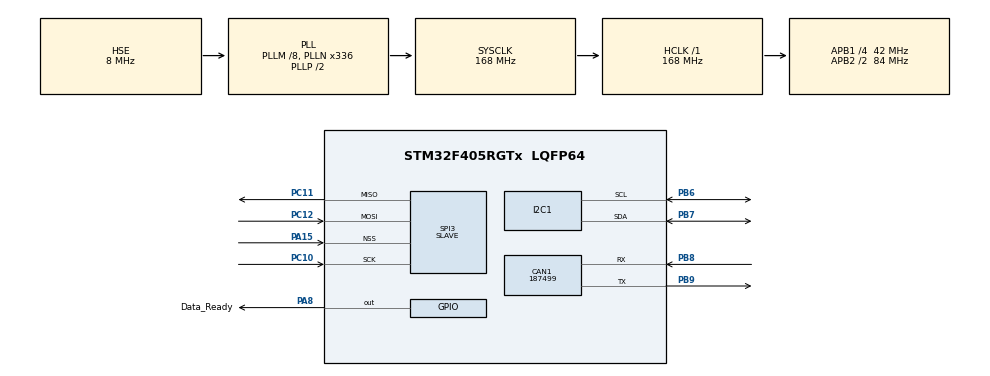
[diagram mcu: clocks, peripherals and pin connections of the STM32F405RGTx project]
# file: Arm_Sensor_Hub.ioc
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CAN1.BS1=CAN_BS1_11TQ
CAN1.BS2=CAN_BS2_2TQ
CAN1.CalculateBaudRate=187499
CAN1.CalculateTimeBit=5333
CAN1.CalculateTimeQuantum=380.95238095238096
Dma.Request0=SPI3_RX
Dma.Request1=SPI3_TX
Dma.SPI3_RX.0.Direction=DMA_PERIPH_TO_MEMORY
Dma.SPI3_RX.0.FIFOMode=DMA_FIFOMODE_DISABLE
Dma.SPI3_RX.0.Instance=DMA1_Stream0
Dma.SPI3_RX.0.MemDataAlignment=DMA_MDATAALIGN_BYTE
Dma.SPI3_RX.0.MemInc=DMA_MINC_ENABLE
Dma.SPI3_RX.0.Mode=DMA_NORMAL
Dma.SPI3_RX.0.PeriphDataAlignment=DMA_PDATAALIGN_BYTE
Dma.SPI3_RX.0.PeriphInc=DMA_PINC_DISABLE
Dma.SPI3_RX.0.Priority=DMA_PRIORITY_VERY_HIGH
Dma.SPI3_TX.1.Direction=DMA_MEMORY_TO_PERIPH
Dma.SPI3_TX.1.FIFOMode=DMA_FIFOMODE_DISABLE
Dma.SPI3_TX.1.Instance=DMA1_Stream5
Dma.SPI3_TX.1.MemDataAlignment=DMA_MDATAALIGN_BYTE
Dma.SPI3_TX.1.MemInc=DMA_MINC_ENABLE
Dma.SPI3_TX.1.Mode=DMA_NORMAL
Dma.SPI3_TX.1.PeriphDataAlignment=DMA_PDATAALIGN_BYTE
Dma.SPI3_TX.1.PeriphInc=DMA_PINC_DISABLE
Dma.SPI3_TX.1.Priority=DMA_PRIORITY_HIGH
FREERTOS.Tasks01=defaultTask,24,128,StartDefaultTask,Default,NULL,Dynamic,NULL,NULL
I2C1.I2C_Mode=I2C_Fast
Mcu.Family=STM32F4
Mcu.Name=STM32F405RGTx
Mcu.Package=LQFP64
NVIC.DMA1_Stream0_IRQn=true\:5\:0\:true\:false\:true\:true\:false\:true\:true
NVIC.DMA1_Stream5_IRQn=true\:6\:0\:true\:false\:true\:true\:false\:true\:true
NVIC.PriorityGroup=NVIC_PRIORITYGROUP_4
NVIC.SPI3_IRQn=true\:5\:0\:false\:false\:true\:true\:true\:true\:true
NVIC.TIM6_DAC_IRQn=true\:15\:0\:false\:false\:true\:false\:false\:true\:true
NVIC.TimeBase=TIM6_DAC_IRQn
NVIC.TimeBaseIP=TIM6
PA13.Mode=Serial_Wire
PA13.Signal=SYS_JTMS-SWDIO
PA14.Mode=Serial_Wire
PA14.Signal=SYS_JTCK-SWCLK
PA15.Mode=NSS_Signal_Hard_Input
PA15.Signal=SPI3_NSS
PA8.GPIO_Label=Data_Ready
PA8.Signal=GPIO_Output
PB6.Mode=I2C
PB6.Signal=I2C1_SCL
PB7.Mode=I2C
PB7.Signal=I2C1_SDA
PB8.Mode=CAN_Activate
PB8.Signal=CAN1_RX
PB9.Mode=CAN_Activate
PB9.Signal=CAN1_TX
PC10.Mode=Full_Duplex_Slave
PC10.Signal=SPI3_SCK
PC11.Mode=Full_Duplex_Slave
PC11.Signal=SPI3_MISO
PC12.Mode=Full_Duplex_Slave
PC12.Signal=SPI3_MOSI
PH0-OSC_IN.Mode=HSE-External-Oscillator
PH0-OSC_IN.Signal=RCC_OSC_IN
PH1-OSC_OUT.Mode=HSE-External-Oscillator
PH1-OSC_OUT.Signal=RCC_OSC_OUT
ProjectManager.HeapSize=0x200
ProjectManager.StackSize=0x400
ProjectManager.TargetToolchain=CMake
RCC.48MHZClocksFreq_Value=48000000
RCC.AHBFreq_Value=168000000
RCC.APB1CLKDivider=RCC_HCLK_DIV4
RCC.APB1Freq_Value=42000000
RCC.APB1TimFreq_Value=84000000
RCC.APB2CLKDivider=RCC_HCLK_DIV2
RCC.APB2Freq_Value=84000000
RCC.APB2TimFreq_Value=168000000
RCC.CortexFreq_Value=168000000
RCC.EnbaleCSS=true
RCC.HCLKFreq_Value=168000000
RCC.HSE_VALUE=8000000
RCC.HSI_VALUE=16000000
RCC.LSE_VALUE=32768
RCC.PLLM=8
RCC.PLLN=336
RCC.PLLQ=7
RCC.PLLSourceVirtual=RCC_PLLSOURCE_HSE
RCC.SYSCLKFreq_VALUE=168000000
RCC.SYSCLKSource=RCC_SYSCLKSOURCE_PLLCLK
RCC.VCOOutputFreq_Value=336000000
SPI3.Direction=SPI_DIRECTION_2LINES
SPI3.Mode=SPI_MODE_SLAVE
SPI3.VirtualNSS=VM_NSSHARD
SPI3.VirtualType=VM_SLAVE
TIM2.Prescaler=83
VP_FREERTOS_VS_CMSIS_V2.Mode=CMSIS_V2
VP_SYS_VS_tim6.Mode=TIM6
VP_TIM2_VS_ClockSourceINT.Mode=Internal
board=custom

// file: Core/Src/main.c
/* USER CODE BEGIN Header */
/**
  ******************************************************************************
  * @file           : main.c
  * @brief          : Main program body
  ******************************************************************************
  * @attention
  *
  * Copyright (c) 2026 STMicroelectronics.
  * All rights reserved.
  *
  * This software is licensed under terms that can be found in the LICENSE file
  * in the root directory of this software component.
  * If no LICENSE file comes with this software, it is provided AS-IS.
  *
  ******************************************************************************
  */
/* USER CODE END Header */
#include "main.h"
#include "cmsis_os.h"

/* USER CODE BEGIN Includes */

#include "app_init.h"
#include "can_service.h"
#include "health_monitor.h"
#include "i2c_manager.h"
#include "sensor_task.h"
#include "spi_slave_service.h"

/* USER CODE END Includes */

CAN_HandleTypeDef hcan1;

I2C_HandleTypeDef hi2c1;

SPI_HandleTypeDef hspi3;
DMA_HandleTypeDef hdma_spi3_rx;
DMA_HandleTypeDef hdma_spi3_tx;

TIM_HandleTypeDef htim2;

/* Definitions for defaultTask */
osThreadId_t defaultTaskHandle;
const osThreadAttr_t defaultTask_attributes = {
  .name = "defaultTask",
  .stack_size = 128 * 4,
  .priority = (osPriority_t) osPriorityNormal,
};

void SystemClock_Config(void);
static void MX_GPIO_Init(void);
static void MX_DMA_Init(void);
static void MX_I2C1_Init(void);
static void MX_SPI3_Init(void);
static void MX_CAN1_Init(void);
static void MX_TIM2_Init(void);
void StartDefaultTask(void *argument);

int main(void)
{

  /* MCU Configuration--------------------------------------------------------*/

  /* Reset of all peripherals, Initializes the Flash interface and the Systick. */
  HAL_Init();

  /* Configure the system clock */
  SystemClock_Config();

  /* Initialize all configured peripherals */
  MX_GPIO_Init();
  MX_DMA_Init();
  MX_I2C1_Init();
  MX_SPI3_Init();
  MX_CAN1_Init();
  MX_TIM2_Init();

  /* Init scheduler */
  osKernelInitialize();

  /* USER CODE BEGIN RTOS_MUTEX */
  /* add mutexes, ... */
  App_Init();
  /* USER CODE END RTOS_MUTEX */

  /* Create the thread(s) */
  /* creation of defaultTask */
  defaultTaskHandle = osThreadNew(StartDefaultTask, NULL, &defaultTask_attributes);

  /* Start scheduler */
  osKernelStart();

  /* We should never get here as control is now taken by the scheduler */

  /* Infinite loop */
  while (1)
  {

  }
}

void SystemClock_Config(void)
{
  RCC_OscInitTypeDef RCC_OscInitStruct = {0};
  RCC_ClkInitTypeDef RCC_ClkInitStruct = {0};

  /** Configure the main internal regulator output voltage
  */
  __HAL_RCC_PWR_CLK_ENABLE();
  __HAL_PWR_VOLTAGESCALING_CONFIG(PWR_REGULATOR_VOLTAGE_SCALE1);

  /** Initializes the RCC Oscillators according to the specified parameters
  * in the RCC_OscInitTypeDef structure.
  */
  RCC_OscInitStruct.OscillatorType = RCC_OSCILLATORTYPE_HSE;
  RCC_OscInitStruct.HSEState = RCC_HSE_ON;
  RCC_OscInitStruct.PLL.PLLState = RCC_PLL_ON;
  RCC_OscInitStruct.PLL.PLLSource = RCC_PLLSOURCE_HSE;
  RCC_OscInitStruct.PLL.PLLM = 8;
  RCC_OscInitStruct.PLL.PLLN = 336;
  RCC_OscInitStruct.PLL.PLLP = RCC_PLLP_DIV2;
  RCC_OscInitStruct.PLL.PLLQ = 7;
  if (HAL_RCC_OscConfig(&RCC_OscInitStruct) != HAL_OK)
  {
    Error_Handler();
  }

  /** Initializes the CPU, AHB and APB buses clocks
  */
  RCC_ClkInitStruct.ClockType = RCC_CLOCKTYPE_HCLK|RCC_CLOCKTYPE_SYSCLK
                              |RCC_CLOCKTYPE_PCLK1|RCC_CLOCKTYPE_PCLK2;
  RCC_ClkInitStruct.SYSCLKSource = RCC_SYSCLKSOURCE_PLLCLK;
  RCC_ClkInitStruct.AHBCLKDivider = RCC_SYSCLK_DIV1;
  RCC_ClkInitStruct.APB1CLKDivider = RCC_HCLK_DIV4;
  RCC_ClkInitStruct.APB2CLKDivider = RCC_HCLK_DIV2;

  if (HAL_RCC_ClockConfig(&RCC_ClkInitStruct, FLASH_LATENCY_5) != HAL_OK)
  {
    Error_Handler();
  }

  /** Enables the Clock Security System
  */
  HAL_RCC_EnableCSS();
}

static void MX_CAN1_Init(void)
{

  hcan1.Instance = CAN1;
  hcan1.Init.Prescaler = 16;
  hcan1.Init.Mode = CAN_MODE_NORMAL;
  hcan1.Init.SyncJumpWidth = CAN_SJW_1TQ;
  hcan1.Init.TimeSeg1 = CAN_BS1_1TQ;
  hcan1.Init.TimeSeg2 = CAN_BS2_1TQ;
  hcan1.Init.TimeTriggeredMode = DISABLE;
  hcan1.Init.AutoBusOff = DISABLE;
  hcan1.Init.AutoWakeUp = DISABLE;
  hcan1.Init.AutoRetransmission = DISABLE;
  hcan1.Init.ReceiveFifoLocked = DISABLE;
  hcan1.Init.TransmitFifoPriority = DISABLE;
  if (HAL_CAN_Init(&hcan1) != HAL_OK)
  {
    Error_Handler();
  }

}

static void MX_I2C1_Init(void)
{

  hi2c1.Instance = I2C1;
  hi2c1.Init.ClockSpeed = 400000;
  hi2c1.Init.DutyCycle = I2C_DUTYCYCLE_2;
  hi2c1.Init.OwnAddress1 = 0;
  hi2c1.Init.AddressingMode = I2C_ADDRESSINGMODE_7BIT;
  hi2c1.Init.DualAddressMode = I2C_DUALADDRESS_DISABLE;
  hi2c1.Init.OwnAddress2 = 0;
  hi2c1.Init.GeneralCallMode = I2C_GENERALCALL_DISABLE;
  hi2c1.Init.NoStretchMode = I2C_NOSTRETCH_DISABLE;
  if (HAL_I2C_Init(&hi2c1) != HAL_OK)
  {
    Error_Handler();
  }

}

static void MX_SPI3_Init(void)
{

  /* SPI3 parameter configuration*/
  hspi3.Instance = SPI3;
  hspi3.Init.Mode = SPI_MODE_SLAVE;
  hspi3.Init.Direction = SPI_DIRECTION_2LINES;
  hspi3.Init.DataSize = SPI_DATASIZE_8BIT;
  hspi3.Init.CLKPolarity = SPI_POLARITY_LOW;
  hspi3.Init.CLKPhase = SPI_PHASE_1EDGE;
  hspi3.Init.NSS = SPI_NSS_HARD_INPUT;
  hspi3.Init.FirstBit = SPI_FIRSTBIT_MSB;
  hspi3.Init.TIMode = SPI_TIMODE_DISABLE;
  hspi3.Init.CRCCalculation = SPI_CRCCALCULATION_DISABLE;
  hspi3.Init.CRCPolynomial = 10;
  if (HAL_SPI_Init(&hspi3) != HAL_OK)
  {
    Error_Handler();
  }

}

static void MX_TIM2_Init(void)
{

  TIM_ClockConfigTypeDef sClockSourceConfig = {0};
  TIM_MasterConfigTypeDef sMasterConfig = {0};

  htim2.Instance = TIM2;
  htim2.Init.Prescaler = 83;
  htim2.Init.CounterMode = TIM_COUNTERMODE_UP;
  htim2.Init.Period = 4294967295;
  htim2.Init.ClockDivision = TIM_CLOCKDIVISION_DIV1;
  htim2.Init.AutoReloadPreload = TIM_AUTORELOAD_PRELOAD_DISABLE;
  if (HAL_TIM_Base_Init(&htim2) != HAL_OK)
  {
    Error_Handler();
  }
  sClockSourceConfig.ClockSource = TIM_CLOCKSOURCE_INTERNAL;
  if (HAL_TIM_ConfigClockSource(&htim2, &sClockSourceConfig) != HAL_OK)
  {
    Error_Handler();
  }
  sMasterConfig.MasterOutputTrigger = TIM_TRGO_RESET;
  sMasterConfig.MasterSlaveMode = TIM_MASTERSLAVEMODE_DISABLE;
  if (HAL_TIMEx_MasterConfigSynchronization(&htim2, &sMasterConfig) != HAL_OK)
  {
    Error_Handler();
  }

}

static void MX_DMA_Init(void)
{

  /* DMA controller clock enable */
  __HAL_RCC_DMA1_CLK_ENABLE();

  /* DMA interrupt init */
  /* DMA1_Stream0_IRQn interrupt configuration */
  HAL_NVIC_SetPriority(DMA1_Stream0_IRQn, 5, 0);
  HAL_NVIC_EnableIRQ(DMA1_Stream0_IRQn);
  /* DMA1_Stream5_IRQn interrupt configuration */
  HAL_NVIC_SetPriority(DMA1_Stream5_IRQn, 6, 0);
  HAL_NVIC_EnableIRQ(DMA1_Stream5_IRQn);

}

static void MX_GPIO_Init(void)
{
  GPIO_InitTypeDef GPIO_InitStruct = {0};

  /* GPIO Ports Clock Enable */
  __HAL_RCC_GPIOH_CLK_ENABLE();
  __HAL_RCC_GPIOA_CLK_ENABLE();
  __HAL_RCC_GPIOC_CLK_ENABLE();
  __HAL_RCC_GPIOB_CLK_ENABLE();

  /*Configure GPIO pin Output Level */
  HAL_GPIO_WritePin(Data_Ready_GPIO_Port, Data_Ready_Pin, GPIO_PIN_RESET);

  /*Configure GPIO pin : Data_Ready_Pin */
  GPIO_InitStruct.Pin = Data_Ready_Pin;
  GPIO_InitStruct.Mode = GPIO_MODE_OUTPUT_PP;
  GPIO_InitStruct.Pull = GPIO_NOPULL;
  GPIO_InitStruct.Speed = GPIO_SPEED_FREQ_LOW;
  HAL_GPIO_Init(Data_Ready_GPIO_Port, &GPIO_InitStruct);

}

void StartDefaultTask(void *argument)
{
  /* USER CODE BEGIN 5 */
  App_Start();

  /* Infinite loop */
  for(;;)
  {
    I2CManager_Process();
    SensorTask_Process();
    CanService_Process();
    SpiSlaveService_Process();
    HealthMonitor_Process();
    osDelay(1);
  }
  /* USER CODE END 5 */
}

void HAL_TIM_PeriodElapsedCallback(TIM_HandleTypeDef *htim)
{
  if (htim->Instance == TIM6)
  {
    HAL_IncTick();
  }
}

void Error_Handler(void)
{
  __disable_irq();
  while (1)
  {
  }
}
